# S32K312_M7 register map
Vendor: NXP Semiconductors; File version: 1.3
CPU: CM7 r0p1, little endian, MPU, FPU, VTOR, 4 interrupt priority bits
Registers are 32-bit, read-write, reset 0x0 unless marked. A register's access mark holds for its fields unless they carry their own. Offsets are from the block's base; [hi:lo] are bit positions; {n}, {i} and the like mark numbered series.

## SDA_AP
Base 0x40254700
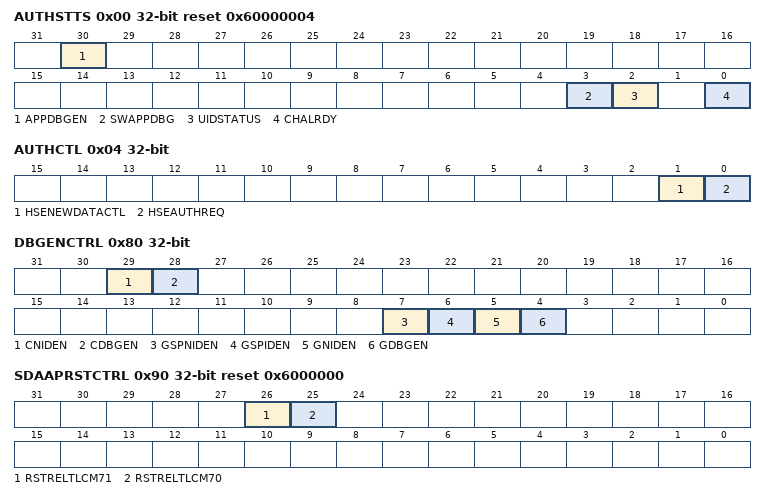
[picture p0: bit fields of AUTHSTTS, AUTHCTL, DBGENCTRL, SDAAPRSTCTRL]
0x00 AUTHSTTS ro reset 0x60000004 — Authentication Status
  [30] APPDBGEN — Application Debug Enabled or Disabled
    0=Application debug disabled; 1=Application debug enabled
  [3] SWAPPDBG — Software Application Debug
    0=Software application debug disabled; 1=Software application debug enabled
  [2] UIDSTATUS — User Identification Status
    0=UID is not ready and is invalid; 1=UID is ready and is valid
  [0] CHALRDY — Challenge Ready
    0=Challenge is not ready; 1=Challenge is ready
0x04 AUTHCTL — Authentication Control
  [1] HSENEWDATACTL — New Data Control
    0=Does not indicate that the debugger has consumed the data registers; 1=Indicates that the debugger has consumed the data registers
  [0] HSEAUTHREQ — Debug Enablement Authentication Request
    0=Does not start the authentication request; 1=Starts the authentication request
{0x10+4i} KEYCHAL[{i}] (i=0..7) ro — Key Challenge
  [31:0] KEYCHAL — Debug Enablement Key Challenge
{0x40+4i} KEYRESP[{i}] (i=0..7) — Key Response
  [31:0] KEYRESP — Debug Enablement Key Response
0x70 UID0 ro — User Identification 0
  [31:0] UID0 — User ID 0
0x74 UID1 ro — User Identification 1
  [31:0] UID1 — User ID 1
0x80 DBGENCTRL reset not defined — Debug Enable Control
  [all] fields
    0=Disabled; 1=Enabled
  [29] CNIDEN — Core Non-Invasive Debug Enable
  [28] CDBGEN — Core Debug Enable
  [7] GSPNIDEN — Global Secure Privileged Non-Invasive Debug Enable
  [6] GSPIDEN — Global Secure Privileged Debug Enable
  [5] GNIDEN — Global Non-Invasive Debug Enable
  [4] GDBGEN — Global Debug Enable
0x90 SDAAPRSTCTRL reset 0x6000000 — Reset Control
  [26] RSTRELTLCM71 — Reset Release Cortex-M7_1
    0=Core is in reset; 1=Reset is released
  [25] RSTRELTLCM70 — Reset Release Cortex-M7_0
    0=Core is in reset; 1=Reset is released
{0xA0+0x10*i} SDAAPGENSTATUS{i} ro (i=0..4) — SDA_AP Generic Status
  [31:0] SDAAPGENSTATUS — DAP Generic Status
0xA4 SDAAPGENCTRL0 — Generic Control 0
  [0] JTAG_CR_EN — JTAG CR Enable
    0=Function performed on the basis of SWJ-DP mode; 1=Function performed on the basis of JTAG mode
0xFC ID ro reset 0x1C0040 — Identity

## PRAMC_0 — PRAMC
Base 0x40264000
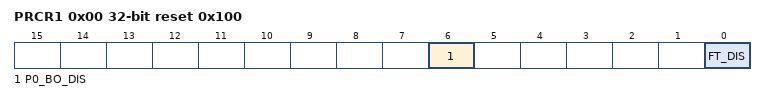
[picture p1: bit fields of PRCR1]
0x00 PRCR1 reset 0x100 — Platform RAM Configuration register 1
  [6] P0_BO_DIS — Port p0 read burst optimization disable.
    0=OPT_YES (64-bit WRP4 read bursts are optimized such that the controller returns a 2-1-1-1 response when PRCR1[FT_DIS ]=1); 1=OPT_NO (64-bit WRP4 read bursts are not optimized; the controller returns a 2-2-2-2 response when PRCR1[FT_DIS ]=1)
  [0] FT_DIS — Flow-through disabled
    0=DIRECT (RAM read data is passed directly to the system bus, incurring no additional latency); 1=REGISTER (RAM read data is registered prior to returning on the system bus, incurring one extra cycle of latency)

## SWT_0 — SWT
Base 0x40270000
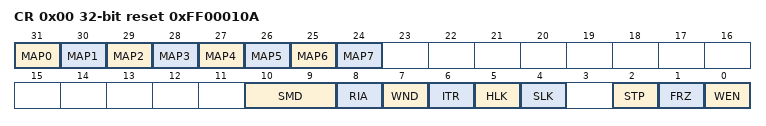
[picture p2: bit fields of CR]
0x00 CR reset 0xFF00010A — Control
  [31-n] MAP{n} (n=0..7) — Master Access Protection {n}
    0=disabled (Access disabled); 1=enabled (Access enabled)
  [10:9] SMD — Service Mode
    0=Fixed Service Sequence; 1=Keyed Service Sequence
  [8] RIA — Reset on Invalid Access
    0=bus_error (Generate a bus error); 1=reset_req (Generate a bus error and reset request)
  [7] WND — Window Mode
    0=Regular mode; 1=windowed (Window mode)
  [6] ITR — Interrupt Then Reset Request
    0=reset_req (Generate a reset request on a timeout); 1=interrupt (Generate an interrupt on an initial timeout; generate a reset request on a second consecutive timeout)
  [5] HLK — Hard Lock
    0=rw (CR, TO, WN, and SK are read/write registers if SLK is also 0); 1=ro (CR, TO, WN, and SK are read-only registers)
  [4] SLK — Soft Lock
    0=rw (CR, TO, WN, and SK are read/write registers if HLK is also 0); 1=ro (CR, TO, WN, and SK are read-only registers)
  [2] STP — Stop Mode Control
    0=continues (Timer continues); 1=stopped (Timer stops)
  [1] FRZ — Debug Mode Control
    0=continues (Timer continues); 1=stopped (Timer stops)
  [0] WEN — Watchdog Enable
    0=disabled; 1=enabled
0x04 IR write-1-clears — Interrupt
  [0] TIF write-1-clears — Timeout Interrupt Flag
    0=no_irq (No interrupt request); 1=irq (Interrupt request due to an initial timeout)
0x08 TO reset 0x320 — Timeout
  [31:0] WTO — Watchdog Timeout
0x0C WN — Window
  [31:0] WST — Window Start Value
0x10 SR — Service
  [15:0] WSC — Watchdog Service Code
0x14 CO ro — Counter Output
  [31:0] CNT — Watchdog Count
0x18 SK — Service Key
  [15:0] SK
0x1C RRR write-1-clears — Event Request
  [0] RRF write-1-clears — Reset Request Flag
    0=no (No reset request); 1=any (Any reset request initiated)
